AUTOSAR XML (schema 4-3-0)
package /App_UART
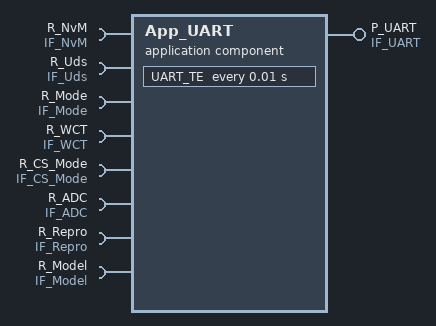
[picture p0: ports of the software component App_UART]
  application sw component type App_UART
    provide port P_UART: nonqueued-sender-com-spec=UART_STR, provided-interface=IF_UART
    8 x require port:
      R_NvM: nonqueued-receiver-com-spec=NvM_STR, required-interface=IF_NvM
      R_Uds: nonqueued-receiver-com-spec=Uds_STR, required-interface=IF_Uds
      R_Mode: nonqueued-receiver-com-spec=Mode_STR, required-interface=IF_Mode
      R_WCT: nonqueued-receiver-com-spec=WCT_STR, required-interface=IF_WCT
      R_CS_Mode: required-com-specs=[ModeInit, NvMInit, ApplicationInit], required-interface=IF_CS_Mode
      R_ADC: nonqueued-receiver-com-spec=ADC_STR, required-interface=IF_ADC
      R_Repro: nonqueued-receiver-com-spec=Repro_STR, required-interface=IF_Repro
      R_Model: nonqueued-receiver-com-spec=Model_STR, required-interface=IF_Model
    behavior InternalBehavior: data-type-mapping=DataTypeMappingSet_WPC
      timing event TE_UART_TE: start-on-event=UART_TE, period=0.01
      runnable UART_TE: symbol=UART_TE_Runnable
        data-receive-point-by-arguments:
          7 x access, all with scope=COMMUNICATION-INTER-ECU:
            DRPBA_UART_TE_R_ADC_Structure: accessed-variable=R_ADC.ADC_STR
            DRPBA_UART_TE_R_Mode_Structure: accessed-variable=R_Mode.Mode_STR
            DRPBA_UART_TE_R_Model_Model_STR: accessed-variable=R_Model.Model_STR
            DRPBA_UART_TE_R_WCT_WCT_STR_ALL: accessed-variable=R_WCT.WCT_STR
            DRPBA_UART_TE_R_Repro_Repro_STR: accessed-variable=R_Repro.Repro_STR
            DRPBA_UART_TE_R_Uds_Uds_STR: accessed-variable=R_Uds.Uds_STR
            DRPBA_UART_TE_R_NvM_NvM_STR: accessed-variable=R_NvM.NvM_STR
        data-send-points:
          access DSP_UART_TE_P_UART_Structure: accessed-variable=P_UART.UART_STR, scope=COMMUNICATION-INTER-ECU
        sync call SSCP_UART_TE_R_CS_Mode_ApplicationInit: operation=R_CS_Mode.ApplicationInit
        sync call SSCP_UART_TE_R_CS_Mode_ModeInit: operation=R_CS_Mode.ModeInit
        sync call SSCP_UART_TE_R_CS_Mode_NvMInit: operation=R_CS_Mode.NvMInit
  sender receiver interface IF_UART  # NFC SWC Output
    data UART_STR: type=IDT_UART_STR
